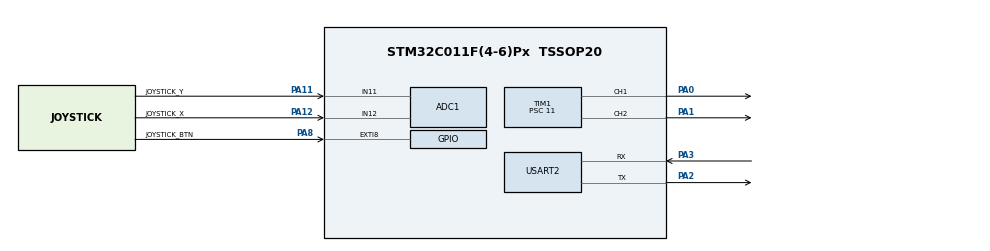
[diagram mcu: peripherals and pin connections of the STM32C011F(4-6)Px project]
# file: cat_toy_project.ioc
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ADC1.Channel-0\#ChannelRegularConversion=ADC_CHANNEL_11
ADC1.Channel-1\#ChannelRegularConversion=ADC_CHANNEL_12
ADC1.DMAContinuousRequests=ENABLE
ADC1.EOCSelection=ADC_EOC_SEQ_CONV
ADC1.ExternalTrigConv=ADC_EXTERNALTRIG_T3_TRGO
ADC1.ExternalTrigConvEdge=ADC_EXTERNALTRIGCONVEDGE_FALLING
ADC1.NbrOfConversion=2
ADC1.NbrOfConversionFlag=1
ADC1.Overrun=ADC_OVR_DATA_OVERWRITTEN
ADC1.Rank-0\#ChannelRegularConversion=1
ADC1.Rank-1\#ChannelRegularConversion=2
ADC1.SamplingTime-0\#ChannelRegularConversion=ADC_SAMPLINGTIME_COMMON_1
ADC1.SamplingTime-1\#ChannelRegularConversion=ADC_SAMPLINGTIME_COMMON_2
ADC1.SelectedChannel=ADC_CHANNEL_11|ADC_CHANNEL_12
ADC1.Sequencer=FULLY_CONFIGURABLE
ADC1.master=1
Dma.ADC1.0.Direction=DMA_PERIPH_TO_MEMORY
Dma.ADC1.0.EventEnable=DISABLE
Dma.ADC1.0.Instance=DMA1_Channel1
Dma.ADC1.0.MemDataAlignment=DMA_MDATAALIGN_HALFWORD
Dma.ADC1.0.MemInc=DMA_MINC_ENABLE
Dma.ADC1.0.Mode=DMA_CIRCULAR
Dma.ADC1.0.PeriphDataAlignment=DMA_PDATAALIGN_HALFWORD
Dma.ADC1.0.PeriphInc=DMA_PINC_DISABLE
Dma.ADC1.0.Polarity=HAL_DMAMUX_REQ_GEN_RISING
Dma.ADC1.0.Priority=DMA_PRIORITY_LOW
Dma.ADC1.0.RequestNumber=1
Dma.ADC1.0.SignalID=NONE
Dma.ADC1.0.SyncEnable=DISABLE
Dma.ADC1.0.SyncPolarity=HAL_DMAMUX_SYNC_NO_EVENT
Dma.ADC1.0.SyncRequestNumber=1
Dma.ADC1.0.SyncSignalID=NONE
Dma.Request0=ADC1
Mcu.Family=STM32C0
Mcu.Name=STM32C011F(4-6)Px
Mcu.Package=TSSOP20
NVIC.DMA1_Channel1_IRQn=true\:0\:0\:false\:false\:true\:false\:true\:true
PA0.Signal=S_TIM1_CH1
PA1.Signal=S_TIM1_CH2
PA11\ [PA9].GPIO_Label=JOYSTICK_Y
PA11\ [PA9].Mode=IN11
PA11\ [PA9].Signal=ADC1_IN11
PA12\ [PA10].GPIO_Label=JOYSTICK_X
PA12\ [PA10].Mode=IN12
PA12\ [PA10].Signal=ADC1_IN12
PA13.Mode=Serial_Wire
PA13.Signal=DEBUG_SWDIO
PA14-BOOT0.Mode=Serial_Wire
PA14-BOOT0.Signal=DEBUG_SWCLK
PA2.Mode=Asynchronous
PA2.Signal=USART2_TX
PA3.Mode=Asynchronous
PA3.Signal=USART2_RX
PA8.GPIO_Label=JOYSTICK_BTN
PA8.Signal=GPXTI8
PC14-OSCX_IN\ (PC14).Mode=HSE-External-Oscillator-REMAPPED
PC14-OSCX_IN\ (PC14).Signal=RCC_OSCX_IN
PC15-OSCX_OUT\ (PC15).Mode=HSE-External-Oscillator-REMAPPED
PC15-OSCX_OUT\ (PC15).Signal=RCC_OSCX_OUT
ProjectManager.HeapSize=0x200
ProjectManager.StackSize=0x400
ProjectManager.TargetToolchain=STM32CubeIDE
RCC.ADCFreq_Value=12000000
RCC.AHBFreq_Value=12000000
RCC.CortexFreq_Value=12000000
RCC.EXTERNAL_CLOCK_VALUE=12288000
RCC.HCLKFreq_Value=12000000
RCC.HSE_VALUE=16000000
RCC.HSI_VALUE=48000000
RCC.LSE_VALUE=32768
RCC.SYSCLKFreq_VALUE=12000000
SH.S_TIM1_CH1.0=TIM1_CH1,PWM Generation1 CH1
SH.S_TIM1_CH2.0=TIM1_CH2,PWM Generation2 CH2
TIM1.AutoReloadPreload=TIM_AUTORELOAD_PRELOAD_ENABLE
TIM1.Channel-PWM\ Generation1\ CH1=TIM_CHANNEL_1
TIM1.Channel-PWM\ Generation2\ CH2=TIM_CHANNEL_2
TIM1.Period=19999
TIM1.Prescaler=11
TIM1.Pulse-PWM\ Generation1\ CH1=1499
TIM1.Pulse-PWM\ Generation2\ CH2=1499
TIM3.AutoReloadPreload=TIM_AUTORELOAD_PRELOAD_ENABLE
TIM3.Period=999
TIM3.Prescaler=11
TIM3.TIM_MasterOutputTrigger=TIM_TRGO_UPDATE
USART2.VirtualMode-Asynchronous=VM_ASYNC
VP_TIM1_VS_ClockSourceINT.Mode=Internal
VP_TIM3_VS_ClockSourceINT.Mode=Internal
board=custom

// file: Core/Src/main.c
/* USER CODE BEGIN Header */
/**
  ******************************************************************************
  * @file           : main.c
  * @brief          : Main program body
  ******************************************************************************
  * @attention
  *
  * Copyright (c) 2024 STMicroelectronics.
  * All rights reserved.
  *
  * This software is licensed under terms that can be found in the LICENSE file
  * in the root directory of this software component.
  * If no LICENSE file comes with this software, it is provided AS-IS.
  *
  ******************************************************************************
  */
/* USER CODE END Header */
#include "main.h"

ADC_HandleTypeDef hadc1;
DMA_HandleTypeDef hdma_adc1;

TIM_HandleTypeDef htim1;
TIM_HandleTypeDef htim3;

UART_HandleTypeDef huart2;

void SystemClock_Config(void);
static void MX_GPIO_Init(void);
static void MX_DMA_Init(void);
static void MX_ADC1_Init(void);
static void MX_TIM1_Init(void);
static void MX_USART2_UART_Init(void);
static void MX_TIM3_Init(void);

int main(void)
{

  /* MCU Configuration--------------------------------------------------------*/

  /* Reset of all peripherals, Initializes the Flash interface and the Systick. */
  HAL_Init();

  /* Configure the system clock */
  SystemClock_Config();

  /* Initialize all configured peripherals */
  MX_GPIO_Init();
  MX_DMA_Init();
  MX_ADC1_Init();
  MX_TIM1_Init();
  MX_USART2_UART_Init();
  MX_TIM3_Init();
  /* USER CODE BEGIN 2 */
  userapp_init();
  /* USER CODE END 2 */

  /* Infinite loop */
  /* USER CODE BEGIN WHILE */
  userapp_loop();
  while (1)
  {
    printf("Application exited...\n");
    HAL_Delay(1000);
    /* USER CODE END WHILE */

  }
}

void SystemClock_Config(void)
{
  RCC_OscInitTypeDef RCC_OscInitStruct = {0};
  RCC_ClkInitTypeDef RCC_ClkInitStruct = {0};

  /** Initializes the RCC Oscillators according to the specified parameters
  * in the RCC_OscInitTypeDef structure.
  */
  RCC_OscInitStruct.OscillatorType = RCC_OSCILLATORTYPE_HSI;
  RCC_OscInitStruct.HSIState = RCC_HSI_ON;
  RCC_OscInitStruct.HSIDiv = RCC_HSI_DIV4;
  RCC_OscInitStruct.HSICalibrationValue = RCC_HSICALIBRATION_DEFAULT;
  if (HAL_RCC_OscConfig(&RCC_OscInitStruct) != HAL_OK)
  {
    Error_Handler();
  }

  /** Initializes the CPU, AHB and APB buses clocks
  */
  RCC_ClkInitStruct.ClockType = RCC_CLOCKTYPE_HCLK|RCC_CLOCKTYPE_SYSCLK
                              |RCC_CLOCKTYPE_PCLK1;
  RCC_ClkInitStruct.SYSCLKSource = RCC_SYSCLKSOURCE_HSI;
  RCC_ClkInitStruct.SYSCLKDivider = RCC_SYSCLK_DIV1;
  RCC_ClkInitStruct.AHBCLKDivider = RCC_HCLK_DIV1;
  RCC_ClkInitStruct.APB1CLKDivider = RCC_APB1_DIV1;

  if (HAL_RCC_ClockConfig(&RCC_ClkInitStruct, FLASH_LATENCY_0) != HAL_OK)
  {
    Error_Handler();
  }
}

static void MX_ADC1_Init(void)
{

  ADC_ChannelConfTypeDef sConfig = {0};

  /** Configure the global features of the ADC (Clock, Resolution, Data Alignment and number of conversion)
  */
  hadc1.Instance = ADC1;
  hadc1.Init.ClockPrescaler = ADC_CLOCK_SYNC_PCLK_DIV1;
  hadc1.Init.Resolution = ADC_RESOLUTION_12B;
  hadc1.Init.DataAlign = ADC_DATAALIGN_RIGHT;
  hadc1.Init.ScanConvMode = ADC_SCAN_ENABLE;
  hadc1.Init.EOCSelection = ADC_EOC_SEQ_CONV;
  hadc1.Init.LowPowerAutoWait = DISABLE;
  hadc1.Init.LowPowerAutoPowerOff = DISABLE;
  hadc1.Init.ContinuousConvMode = DISABLE;
  hadc1.Init.NbrOfConversion = 2;
  hadc1.Init.DiscontinuousConvMode = DISABLE;
  hadc1.Init.ExternalTrigConv = ADC_EXTERNALTRIG_T3_TRGO;
  hadc1.Init.ExternalTrigConvEdge = ADC_EXTERNALTRIGCONVEDGE_FALLING;
  hadc1.Init.DMAContinuousRequests = ENABLE;
  hadc1.Init.Overrun = ADC_OVR_DATA_OVERWRITTEN;
  hadc1.Init.SamplingTimeCommon1 = ADC_SAMPLETIME_1CYCLE_5;
  hadc1.Init.SamplingTimeCommon2 = ADC_SAMPLETIME_1CYCLE_5;
  hadc1.Init.OversamplingMode = DISABLE;
  hadc1.Init.TriggerFrequencyMode = ADC_TRIGGER_FREQ_HIGH;
  if (HAL_ADC_Init(&hadc1) != HAL_OK)
  {
    Error_Handler();
  }

  /** Configure Regular Channel
  */
  sConfig.Channel = ADC_CHANNEL_11;
  sConfig.Rank = ADC_REGULAR_RANK_1;
  sConfig.SamplingTime = ADC_SAMPLINGTIME_COMMON_1;
  if (HAL_ADC_ConfigChannel(&hadc1, &sConfig) != HAL_OK)
  {
    Error_Handler();
  }

  /** Configure Regular Channel
  */
  sConfig.Channel = ADC_CHANNEL_12;
  sConfig.Rank = ADC_REGULAR_RANK_2;
  sConfig.SamplingTime = ADC_SAMPLINGTIME_COMMON_2;
  if (HAL_ADC_ConfigChannel(&hadc1, &sConfig) != HAL_OK)
  {
    Error_Handler();
  }

}

static void MX_TIM1_Init(void)
{

  TIM_ClockConfigTypeDef sClockSourceConfig = {0};
  TIM_MasterConfigTypeDef sMasterConfig = {0};
  TIM_OC_InitTypeDef sConfigOC = {0};
  TIM_BreakDeadTimeConfigTypeDef sBreakDeadTimeConfig = {0};

  htim1.Instance = TIM1;
  htim1.Init.Prescaler = 11;
  htim1.Init.CounterMode = TIM_COUNTERMODE_UP;
  htim1.Init.Period = 19999;
  htim1.Init.ClockDivision = TIM_CLOCKDIVISION_DIV1;
  htim1.Init.RepetitionCounter = 0;
  htim1.Init.AutoReloadPreload = TIM_AUTORELOAD_PRELOAD_ENABLE;
  if (HAL_TIM_Base_Init(&htim1) != HAL_OK)
  {
    Error_Handler();
  }
  sClockSourceConfig.ClockSource = TIM_CLOCKSOURCE_INTERNAL;
  if (HAL_TIM_ConfigClockSource(&htim1, &sClockSourceConfig) != HAL_OK)
  {
    Error_Handler();
  }
  if (HAL_TIM_PWM_Init(&htim1) != HAL_OK)
  {
    Error_Handler();
  }
  sMasterConfig.MasterOutputTrigger = TIM_TRGO_RESET;
  sMasterConfig.MasterOutputTrigger2 = TIM_TRGO2_RESET;
  sMasterConfig.MasterSlaveMode = TIM_MASTERSLAVEMODE_DISABLE;
  if (HAL_TIMEx_MasterConfigSynchronization(&htim1, &sMasterConfig) != HAL_OK)
  {
    Error_Handler();
  }
  sConfigOC.OCMode = TIM_OCMODE_PWM1;
  sConfigOC.Pulse = 1499;
  sConfigOC.OCPolarity = TIM_OCPOLARITY_HIGH;
  sConfigOC.OCNPolarity = TIM_OCNPOLARITY_HIGH;
  sConfigOC.OCFastMode = TIM_OCFAST_DISABLE;
  sConfigOC.OCIdleState = TIM_OCIDLESTATE_RESET;
  sConfigOC.OCNIdleState = TIM_OCNIDLESTATE_RESET;
  if (HAL_TIM_PWM_ConfigChannel(&htim1, &sConfigOC, TIM_CHANNEL_1) != HAL_OK)
  {
    Error_Handler();
  }
  if (HAL_TIM_PWM_ConfigChannel(&htim1, &sConfigOC, TIM_CHANNEL_2) != HAL_OK)
  {
    Error_Handler();
  }
  sBreakDeadTimeConfig.OffStateRunMode = TIM_OSSR_DISABLE;
  sBreakDeadTimeConfig.OffStateIDLEMode = TIM_OSSI_DISABLE;
  sBreakDeadTimeConfig.LockLevel = TIM_LOCKLEVEL_OFF;
  sBreakDeadTimeConfig.DeadTime = 0;
  sBreakDeadTimeConfig.BreakState = TIM_BREAK_DISABLE;
  sBreakDeadTimeConfig.BreakPolarity = TIM_BREAKPOLARITY_HIGH;
  sBreakDeadTimeConfig.BreakFilter = 0;
  sBreakDeadTimeConfig.BreakAFMode = TIM_BREAK_AFMODE_INPUT;
  sBreakDeadTimeConfig.Break2State = TIM_BREAK2_DISABLE;
  sBreakDeadTimeConfig.Break2Polarity = TIM_BREAK2POLARITY_HIGH;
  sBreakDeadTimeConfig.Break2Filter = 0;
  sBreakDeadTimeConfig.Break2AFMode = TIM_BREAK_AFMODE_INPUT;
  sBreakDeadTimeConfig.AutomaticOutput = TIM_AUTOMATICOUTPUT_DISABLE;
  if (HAL_TIMEx_ConfigBreakDeadTime(&htim1, &sBreakDeadTimeConfig) != HAL_OK)
  {
    Error_Handler();
  }
  HAL_TIM_MspPostInit(&htim1);

}

static void MX_TIM3_Init(void)
{

  TIM_ClockConfigTypeDef sClockSourceConfig = {0};
  TIM_MasterConfigTypeDef sMasterConfig = {0};

  htim3.Instance = TIM3;
  htim3.Init.Prescaler = 11;
  htim3.Init.CounterMode = TIM_COUNTERMODE_UP;
  htim3.Init.Period = 999;
  htim3.Init.ClockDivision = TIM_CLOCKDIVISION_DIV1;
  htim3.Init.AutoReloadPreload = TIM_AUTORELOAD_PRELOAD_ENABLE;
  if (HAL_TIM_Base_Init(&htim3) != HAL_OK)
  {
    Error_Handler();
  }
  sClockSourceConfig.ClockSource = TIM_CLOCKSOURCE_INTERNAL;
  if (HAL_TIM_ConfigClockSource(&htim3, &sClockSourceConfig) != HAL_OK)
  {
    Error_Handler();
  }
  sMasterConfig.MasterOutputTrigger = TIM_TRGO_UPDATE;
  sMasterConfig.MasterSlaveMode = TIM_MASTERSLAVEMODE_DISABLE;
  if (HAL_TIMEx_MasterConfigSynchronization(&htim3, &sMasterConfig) != HAL_OK)
  {
    Error_Handler();
  }

}

static void MX_USART2_UART_Init(void)
{

  huart2.Instance = USART2;
  huart2.Init.BaudRate = 115200;
  huart2.Init.WordLength = UART_WORDLENGTH_8B;
  huart2.Init.StopBits = UART_STOPBITS_1;
  huart2.Init.Parity = UART_PARITY_NONE;
  huart2.Init.Mode = UART_MODE_TX_RX;
  huart2.Init.HwFlowCtl = UART_HWCONTROL_NONE;
  huart2.Init.OverSampling = UART_OVERSAMPLING_16;
  huart2.Init.OneBitSampling = UART_ONE_BIT_SAMPLE_DISABLE;
  huart2.Init.ClockPrescaler = UART_PRESCALER_DIV1;
  huart2.AdvancedInit.AdvFeatureInit = UART_ADVFEATURE_NO_INIT;
  if (HAL_UART_Init(&huart2) != HAL_OK)
  {
    Error_Handler();
  }

}

static void MX_DMA_Init(void)
{

  /* DMA controller clock enable */
  __HAL_RCC_DMA1_CLK_ENABLE();

  /* DMA interrupt init */
  /* DMA1_Channel1_IRQn interrupt configuration */
  HAL_NVIC_SetPriority(DMA1_Channel1_IRQn, 0, 0);
  HAL_NVIC_EnableIRQ(DMA1_Channel1_IRQn);

}

static void MX_GPIO_Init(void)
{
  GPIO_InitTypeDef GPIO_InitStruct = {0};

  /* GPIO Ports Clock Enable */
  __HAL_RCC_GPIOC_CLK_ENABLE();
  __HAL_RCC_GPIOA_CLK_ENABLE();

  /*Configure GPIO pin : JOYSTICK_BTN_Pin */
  GPIO_InitStruct.Pin = JOYSTICK_BTN_Pin;
  GPIO_InitStruct.Mode = GPIO_MODE_IT_RISING;
  GPIO_InitStruct.Pull = GPIO_NOPULL;
  HAL_GPIO_Init(JOYSTICK_BTN_GPIO_Port, &GPIO_InitStruct);

}

void Error_Handler(void)
{
  __disable_irq();
  while (1)
  {
  }
}
